# STM32MP157x register map
File version: 1.3
Registers are 32-bit, read-write, reset 0x0 unless marked. A register's access mark holds for its fields unless they carry their own. Offsets are from the block's base; [hi:lo] are bit positions; {n}, {i} and the like mark numbered series.

## CCU
Base 0x44010000
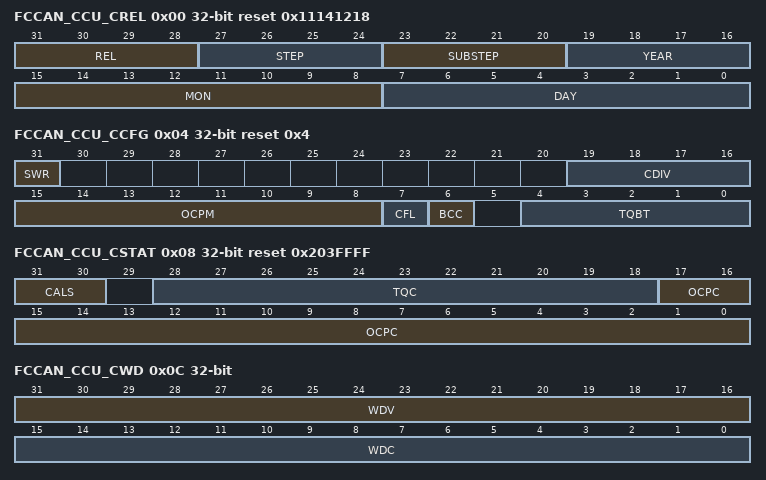
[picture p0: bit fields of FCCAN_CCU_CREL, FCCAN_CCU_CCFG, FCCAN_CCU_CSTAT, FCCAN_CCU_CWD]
0x00 FCCAN_CCU_CREL ro reset 0x11141218 — Clock calibration unit core release register
  [31:28] REL, [27:24] STEP, [23:20] SUBSTEP, [19:16] YEAR, [15:8] MON, [7:0] DAY
0x04 FCCAN_CCU_CCFG reset 0x4 — Calibration configuration register
  [31] SWR, [19:16] CDIV, [15:8] OCPM, [7] CFL, [6] BCC, [4:0] TQBT
0x08 FCCAN_CCU_CSTAT ro reset 0x203FFFF — Calibration status register
  [31:30] CALS, [28:18] TQC, [17:0] OCPC
0x0C FCCAN_CCU_CWD access per field — The calibration watchdog is started after the first falling edge when the calibration FSM is in state Not_Calibrated (CCU_CSTAT.CALS = 00). In this state the calibration watchdog monitors the message received. In case no message was received until the calibration watchdog has counted down to 0, the calibration FSM stays in state Not_Calibrated (CCU_CSTAT.CALS = 00), the counter is reloaded with FDCAN_RWD.WDC and basic calibration is restarted after the next falling edge. When in state Basic_Calibrated (CCU_CSTAT.CALS = 01), the calibration watchdog is restarted with each received message . In case no message was received until the calibration watchdog has counted down to 0, the calibration FSM returns to state Not_Calibrated (CCU_CSTAT.CALS = 00), the counter is reloaded with FDCAN_RWD.WDC and basic calibration is restarted after the next falling edge. When a quartz message is received, state Precision_Calibrated (CCU_CSTAT.CALS = 10) is entered and the calibration watchdog is restarted. In this state the calibration watchdog monitors the quartz message received input. In case no message from a quartz controlled node is received by the attached TTCAN until the calibration watchdog has counted down to 0, the calibration FSM transits back to state Basic_Calibrated (CCU_CSTAT.CALS = 01). The signal is active when the CAN protocol engine on the attached TTCAN is started i.e. when the INIT bit is reset. A calibration watchdog event also sets interrupt flag CCU_IR.CWE. If enabled by CCU_IE.CWEE, interrupt line is activated (set to high). Interrupt line remains active until interrupt flag CCU_IR.CWE is reset.
  [31:16] WDV ro, [15:0] WDC rw
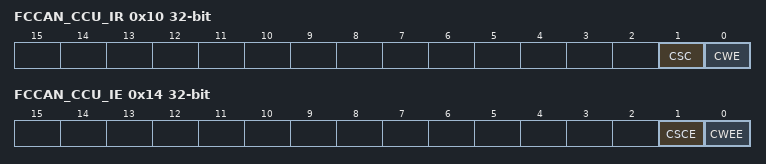
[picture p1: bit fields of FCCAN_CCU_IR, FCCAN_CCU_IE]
0x10 FCCAN_CCU_IR — The flags are set when one of the listed conditions is detected (edge-sensitive). The flags remain set until the Host clears them. A flag is cleared by writing a 1 to the corresponding bit position. Writing a 0 has no effect. A hard reset will clear the register. The configuration of CCU_IE controls whether an interrupt is generated or not.
  [1] CSC, [0] CWE
0x14 FCCAN_CCU_IE — The settings in the CU interrupt enable register determine whether a status change in the CU interrupt register will be signaled on an interrupt line.
  [1] CSCE, [0] CWEE

## GICD
Base 0xA0021000
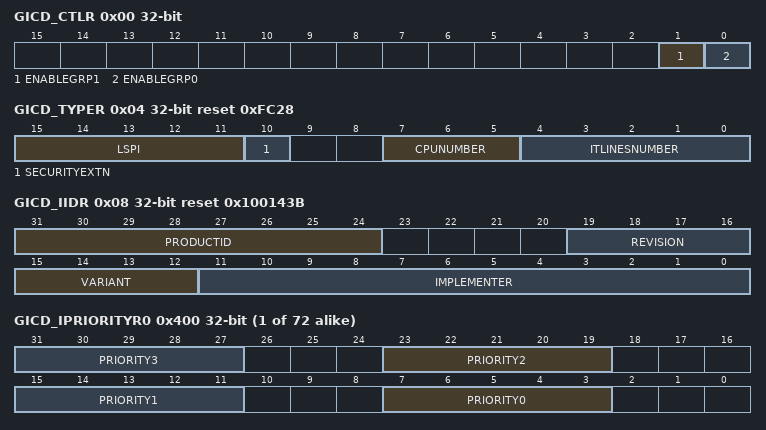
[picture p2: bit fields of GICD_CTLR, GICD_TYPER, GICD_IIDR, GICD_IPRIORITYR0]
0x00 GICD_CTLR — GICD control register
  [1] ENABLEGRP1, [0] ENABLEGRP0
0x04 GICD_TYPER ro reset 0xFC28 — GICD interrupt controller type register
  [15:11] LSPI, [10] SECURITYEXTN, [7:5] CPUNUMBER, [4:0] ITLINESNUMBER
0x08 GICD_IIDR ro reset 0x100143B — GICD implementer identification register
  [31:24] PRODUCTID, [19:16] REVISION, [15:12] VARIANT, [11:0] IMPLEMENTER
{0x80+4i} GICD_IGROUPR{i} (i=0..2) — For interrupts ID
0x8C GICD_IGROUPR3 — For interrupts ID = x*32 to ID = x*32+31
0x90 GICD_IGROUPR4 — For interrupts ID = x*32 to ID = x*32+31
{0x80+4i} GICD_IGROUPR{i} (i=5..8) — For interrupts ID
0x100 GICD_ISENABLER0 reset 0xFFFF — For interrupts ID = 0 to ID = 31
{0x100+4i} GICD_ISENABLER{i} (i=1..8) — For interrupts ID
0x180 GICD_ICENABLER0 reset 0xFFFF — For interrupts ID = 0 to ID = 31
{0x180+4i} GICD_ICENABLER{i} (i=1..8) — For interrupts ID
{0x200+4i} GICD_ISPENDR{i} (i=0..8) — For interrupts ID
{0x280+4i} GICD_ICPENDR{i} (i=0..8) — For interrupts ID
{0x300+4i} GICD_ISACTIVER{i} (i=0..8) — For interrupts ID
{0x380+4i} GICD_ICACTIVER{i} (i=0..8) — For interrupts ID
{0x400+4i} GICD_IPRIORITYR{i} (i=0..71) — GICD interrupt priority register {i}
  [8n+7:8n+3] PRIORITY{n} (n=0..3)
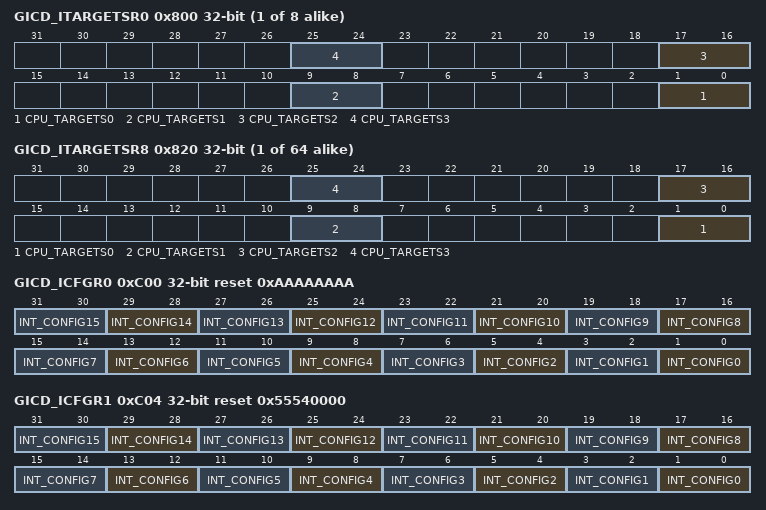
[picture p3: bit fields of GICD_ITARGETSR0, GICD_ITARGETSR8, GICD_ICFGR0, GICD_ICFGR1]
{0x800+4i} GICD_ITARGETSR{i} ro (i=0..7) — For existing SGIs and PPIs, read of CPU targets field returns the number of the processor performing the read.
  [8n+1:8n] CPU_TARGETS{n} (n=0..3)
{0x800+4i} GICD_ITARGETSR{i} (i=8..71) — GICD interrupt processor target register {i}
  [8n+1:8n] CPU_TARGETS{n} (n=0..3)
0xC00 GICD_ICFGR0 reset 0xAAAAAAAA — GICD interrupt configuration register
  [2n+1:2n] INT_CONFIG{n} (n=0..15)
0xC04 GICD_ICFGR1 reset 0x55540000 — GICD interrupt configuration register
  [2n+1:2n] INT_CONFIG{n} (n=0..15)
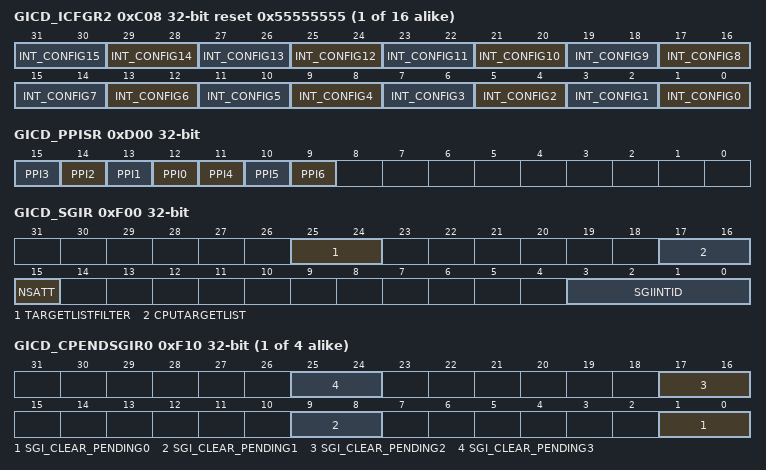
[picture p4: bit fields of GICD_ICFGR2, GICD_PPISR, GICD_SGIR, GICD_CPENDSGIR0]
{0xC00+4i} GICD_ICFGR{i} reset 0x55555555 (i=2..17) — GICD interrupt configuration register {i}
  [2n+1:2n] INT_CONFIG{n} (n=0..15)
0xD00 GICD_PPISR ro — GICD private peripheral interrupt status register
  [n+12] PPI{n} (n=0..3), [11] PPI4, [10] PPI5, [9] PPI6
0xD08 GICD_SPISR1 ro — For interrupts ID = SPI number+32, from SPI [x*32+31] to SPI [x*32]
{0xD04+4i} GICD_SPISR{i} ro (i=2..7) — For interrupts ID
0xF00 GICD_SGIR wo — GICD software generated interrupt register
  [25:24] TARGETLISTFILTER, [17:16] CPUTARGETLIST, [15] NSATT, [3:0] SGIINTID
{0xF10+4i} GICD_CPENDSGIR{i} (i=0..3) — For SGI x*4 to SGI x*4+3
  [8n+1:8n] SGI_CLEAR_PENDING{n} (n=0..3)
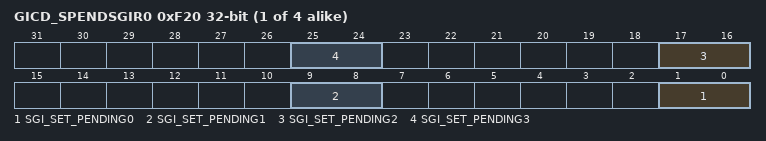
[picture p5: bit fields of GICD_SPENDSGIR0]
{0xF20+4i} GICD_SPENDSGIR{i} (i=0..3) — For SGI x*4 to SGI x*4+3
  [8n+1:8n] SGI_SET_PENDING{n} (n=0..3)
0xFD0 GICD_PIDR4 ro reset 0x4 — GICD peripheral ID4 register
{0xFC0+4i} GICD_PIDR{i} ro (i=5..7) — GICD peripheral ID5 to ID7 register {i}
0xFE0 GICD_PIDR0 ro reset 0x90 — GICD peripheral ID0 register
0xFE4 GICD_PIDR1 ro reset 0xB4 — GICD peripheral ID1 register
0xFE8 GICD_PIDR2 ro reset 0x2B — GICD peripheral ID2 register
0xFEC GICD_PIDR3 ro — GICD peripheral ID3 register
0xFF0 GICD_CIDR0 ro reset 0xD — GICD component ID0 register
0xFF4 GICD_CIDR1 ro reset 0xF0 — GICD component ID1 register
0xFF8 GICD_CIDR2 ro reset 0x5 — GICD component ID2 register
0xFFC GICD_CIDR3 ro reset 0xB1 — GICD component ID3 register
